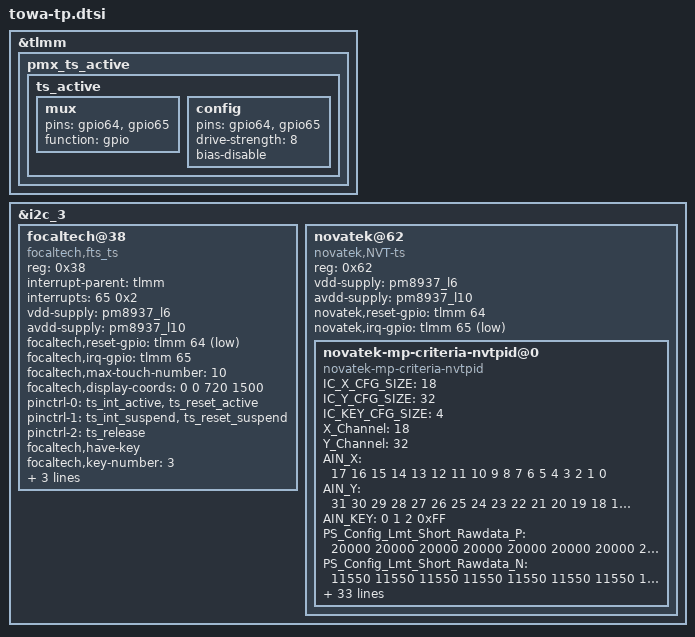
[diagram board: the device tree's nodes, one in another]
/*
 * Copyright (c) 2015, The Linux Foundation. All rights reserved.
 *
 * This program is free software; you can redistribute it and/or modify
 * it under the terms of the GNU General Public License version 2 and
 * only version 2 as published by the Free Software Foundation.
 *
 * This program is distributed in the hope that it will be useful,
 * but WITHOUT ANY WARRANTY; without even the implied warranty of
 * MERCHANTABILITY or FITNESS FOR A PARTICULAR PURPOSE.  See the
 * GNU General Public License for more details.
 */

&tlmm {
	pmx_ts_active {
		ts_active: ts_active {
			mux {
				pins = "gpio64","gpio65";
				function = "gpio";
			};

			config {
				pins = "gpio64","gpio65";
				drive-strength = <8>;
				bias-disable; /* NO pull */
			};
		};
	};
};

&i2c_3 {
	status = "ok";
	/* focaltech device tree node */
        focaltech@38 {
                compatible = "focaltech,fts_ts";
                reg = <0x38>;
                interrupt-parent = <&tlmm>;
                interrupts = <65 0x2>;
		vdd-supply = <&pm8937_l6>;    //VDDIO
		avdd-supply = <&pm8937_l10>;    //VDD

                focaltech,reset-gpio = <&tlmm 64 0x01>;
                focaltech,irq-gpio = <&tlmm 65 0x02>;

		/* INT脚 */
		focaltech,max-touch-number = <10>;
		/* 最大触点数 */
		focaltech,display-coords = <0 0 720 1500>;
		/* 分辨率 */

                /* pins used by touchscreen */
                pinctrl-names = "pmx_ts_active",
                                "pmx_ts_suspend",
                                "pmx_ts_release";
                pinctrl-0 = <&ts_int_active &ts_reset_active>;
                pinctrl-1 = <&ts_int_suspend &ts_reset_suspend>;
                pinctrl-2 = <&ts_release>;
		/* 按键配置 */
		/*focaltech,have-key;*/
		/* 无按键 */
		/* 有按键 */
		focaltech,have-key;
		focaltech,key-number = <3>; /* 按键个数 */
		focaltech,keys = <139 172 158>; /* 按键值,参考上面*/
		focaltech,key-y-coord = <2000>; /* 按键Y坐标 */
		focaltech,key-x-coords = <200 600 800>; /* 按键对应的X坐标 */
	};

	/* Novatek device tree node */
	novatek@62 {
		compatible = "novatek,NVT-ts";
		reg = <0x62>;
		status = "ok";

		vdd-supply = <&pm8937_l6>;    //VDDIO
		avdd-supply = <&pm8937_l10>;    //VDD

		novatek,reset-gpio = <&tlmm 64 0x00>;
		novatek,irq-gpio = <&tlmm 65 0x2001>;

		/* MP */
		//novatek,mp-support-dt;

		novatek-mp-criteria-nvtpid@0 {
			#address-cells = <1>;
			#size-cells = <0>;
			compatible = "novatek-mp-criteria-nvtpid";

			/* MP Config */
			IC_X_CFG_SIZE = <18>;
			IC_Y_CFG_SIZE = <32>;
			IC_KEY_CFG_SIZE = <4>;
			X_Channel = <18>;
			Y_Channel = <32>;
			AIN_X = <17 16 15 14 13 12 11 10 9 8 7 6 5 4 3 2 1 0>;
			AIN_Y = <31 30 29 28 27 26 25 24 23 22 21 20 19 18 17 16 15
								14 13 12 11 10 9 8 7 6 5 4 3 2 1 0>;
			AIN_KEY = <0 1 2 0xFF>;

			/* MP Criteria */
			PS_Config_Lmt_Short_Rawdata_P = <
				20000 20000 20000 20000 20000 20000 20000 20000 20000 20000 20000 20000 20000 20000 20000 20000 20000 20000
				20000 20000 20000 20000 20000 20000 20000 20000 20000 20000 20000 20000 20000 20000 20000 20000 20000 20000
				20000 20000 20000 20000 20000 20000 20000 20000 20000 20000 20000 20000 20000 20000 20000 20000 20000 20000
				20000 20000 20000 20000 20000 20000 20000 20000 20000 20000 20000 20000 20000 20000 20000 20000 20000 20000
				20000 20000 20000 20000 20000 20000 20000 20000 20000 20000 20000 20000 20000 20000 20000 20000 20000 20000
				20000 20000 20000 20000 20000 20000 20000 20000 20000 20000 20000 20000 20000 20000 20000 20000 20000 20000
				20000 20000 20000 20000 20000 20000 20000 20000 20000 20000 20000 20000 20000 20000 20000 20000 20000 20000
				20000 20000 20000 20000 20000 20000 20000 20000 20000 20000 20000 20000 20000 20000 20000 20000 20000 20000
				20000 20000 20000 20000 20000 20000 20000 20000 20000 20000 20000 20000 20000 20000 20000 20000 20000 20000
				20000 20000 20000 20000 20000 20000 20000 20000 20000 20000 20000 20000 20000 20000 20000 20000 20000 20000
				20000 20000 20000 20000 20000 20000 20000 20000 20000 20000 20000 20000 20000 20000 20000 20000 20000 20000
				20000 20000 20000 20000 20000 20000 20000 20000 20000 20000 20000 20000 20000 20000 20000 20000 20000 20000
				20000 20000 20000 20000 20000 20000 20000 20000 20000 20000 20000 20000 20000 20000 20000 20000 20000 20000
				20000 20000 20000 20000 20000 20000 20000 20000 20000 20000 20000 20000 20000 20000 20000 20000 20000 20000
				20000 20000 20000 20000 20000 20000 20000 20000 20000 20000 20000 20000 20000 20000 20000 20000 20000 20000
				20000 20000 20000 20000 20000 20000 20000 20000 20000 20000 20000 20000 20000 20000 20000 20000 20000 20000
				20000 20000 20000 20000 20000 20000 20000 20000 20000 20000 20000 20000 20000 20000 20000 20000 20000 20000
				20000 20000 20000 20000 20000 20000 20000 20000 20000 20000 20000 20000 20000 20000 20000 20000 20000 20000
				20000 20000 20000 20000 20000 20000 20000 20000 20000 20000 20000 20000 20000 20000 20000 20000 20000 20000
				20000 20000 20000 20000 20000 20000 20000 20000 20000 20000 20000 20000 20000 20000 20000 20000 20000 20000
				20000 20000 20000 20000 20000 20000 20000 20000 20000 20000 20000 20000 20000 20000 20000 20000 20000 20000
				20000 20000 20000 20000 20000 20000 20000 20000 20000 20000 20000 20000 20000 20000 20000 20000 20000 20000
				20000 20000 20000 20000 20000 20000 20000 20000 20000 20000 20000 20000 20000 20000 20000 20000 20000 20000
				20000 20000 20000 20000 20000 20000 20000 20000 20000 20000 20000 20000 20000 20000 20000 20000 20000 20000
				20000 20000 20000 20000 20000 20000 20000 20000 20000 20000 20000 20000 20000 20000 20000 20000 20000 20000
				20000 20000 20000 20000 20000 20000 20000 20000 20000 20000 20000 20000 20000 20000 20000 20000 20000 20000
				20000 20000 20000 20000 20000 20000 20000 20000 20000 20000 20000 20000 20000 20000 20000 20000 20000 20000
				20000 20000 20000 20000 20000 20000 20000 20000 20000 20000 20000 20000 20000 20000 20000 20000 20000 20000
				20000 20000 20000 20000 20000 20000 20000 20000 20000 20000 20000 20000 20000 20000 20000 20000 20000 20000
				20000 20000 20000 20000 20000 20000 20000 20000 20000 20000 20000 20000 20000 20000 20000 20000 20000 20000
				20000 20000 20000 20000 20000 20000 20000 20000 20000 20000 20000 20000 20000 20000 20000 20000 20000 20000
				20000 20000 20000 20000 20000 20000 20000 20000 20000 20000 20000 20000 20000 20000 20000 20000 20000 20000
				20000 20000 20000>;

			PS_Config_Lmt_Short_Rawdata_N = <
				11550 11550 11550 11550 11550 11550 11550 11550 11550 11550 11550 11550 11550 11550 11550 11550 11550 11550
				11550 11550 11550 11550 11550 11550 11550 11550 11550 11550 11550 11550 11550 11550 11550 11550 11550 11550
				11550 11550 11550 11550 11550 11550 11550 11550 11550 11550 11550 11550 11550 11550 11550 11550 11550 11550
				11550 11550 11550 11550 11550 11550 11550 11550 11550 11550 11550 11550 11550 11550 11550 11550 11550 11550
				11550 11550 11550 11550 11550 11550 11550 11550 11550 11550 11550 11550 11550 11550 11550 11550 11550 11550
				11550 11550 11550 11550 11550 11550 11550 11550 11550 11550 11550 11550 11550 11550 11550 11550 11550 11550
				11550 11550 11550 11550 11550 11550 11550 11550 11550 11550 11550 11550 11550 11550 11550 11550 11550 11550
				11550 11550 11550 11550 11550 11550 11550 11550 11550 11550 11550 11550 11550 11550 11550 11550 11550 11550
				11550 11550 11550 11550 11550 11550 11550 11550 11550 11550 11550 11550 11550 11550 11550 11550 11550 11550
				11550 11550 11550 11550 11550 11550 11550 11550 11550 11550 11550 11550 11550 11550 11550 11550 11550 11550
				11550 11550 11550 11550 11550 11550 11550 11550 11550 11550 11550 11550 11550 11550 11550 11550 11550 11550
				11550 11550 11550 11550 11550 11550 11550 11550 11550 11550 11550 11550 11550 11550 11550 11550 11550 11550
				11550 11550 11550 11550 11550 11550 11550 11550 11550 11550 11550 11550 11550 11550 11550 11550 11550 11550
				11550 11550 11550 11550 11550 11550 11550 11550 11550 11550 11550 11550 11550 11550 11550 11550 11550 11550
				11550 11550 11550 11550 11550 11550 11550 11550 11550 11550 11550 11550 11550 11550 11550 11550 11550 11550
				11550 11550 11550 11550 11550 11550 11550 11550 11550 11550 11550 11550 11550 11550 11550 11550 11550 11550
				11550 11550 11550 11550 11550 11550 11550 11550 11550 11550 11550 11550 11550 11550 11550 11550 11550 11550
				11550 11550 11550 11550 11550 11550 11550 11550 11550 11550 11550 11550 11550 11550 11550 11550 11550 11550
				11550 11550 11550 11550 11550 11550 11550 11550 11550 11550 11550 11550 11550 11550 11550 11550 11550 11550
				11550 11550 11550 11550 11550 11550 11550 11550 11550 11550 11550 11550 11550 11550 11550 11550 11550 11550
				11550 11550 11550 11550 11550 11550 11550 11550 11550 11550 11550 11550 11550 11550 11550 11550 11550 11550
				11550 11550 11550 11550 11550 11550 11550 11550 11550 11550 11550 11550 11550 11550 11550 11550 11550 11550
				11550 11550 11550 11550 11550 11550 11550 11550 11550 11550 11550 11550 11550 11550 11550 11550 11550 11550
				11550 11550 11550 11550 11550 11550 11550 11550 11550 11550 11550 11550 11550 11550 11550 11550 11550 11550
				11550 11550 11550 11550 11550 11550 11550 11550 11550 11550 11550 11550 11550 11550 11550 11550 11550 11550
				11550 11550 11550 11550 11550 11550 11550 11550 11550 11550 11550 11550 11550 11550 11550 11550 11550 11550
				11550 11550 11550 11550 11550 11550 11550 11550 11550 11550 11550 11550 11550 11550 11550 11550 11550 11550
				11550 11550 11550 11550 11550 11550 11550 11550 11550 11550 11550 11550 11550 11550 11550 11550 11550 11550
				11550 11550 11550 11550 11550 11550 11550 11550 11550 11550 11550 11550 11550 11550 11550 11550 11550 11550
				11550 11550 11550 11550 11550 11550 11550 11550 11550 11550 11550 11550 11550 11550 11550 11550 11550 11550
				11550 11550 11550 11550 11550 11550 11550 11550 11550 11550 11550 11550 11550 11550 11550 11550 11550 11550
				11550 11550 11550 11550 11550 11550 11550 11550 11550 11550 11550 11550 11550 11550 11550 11550 11550 11550
				11550 11550 11550>;

			PS_Config_Lmt_Short_Diff_P = <
				6300 6300 6300 6300 6300 6300 6300 6300 6300 6300 6300 6300 6300 6300 6300 6300 6300 6300
				6300 6300 6300 6300 6300 6300 6300 6300 6300 6300 6300 6300 6300 6300 6300 6300 6300 6300
				6300 6300 6300 6300 6300 6300 6300 6300 6300 6300 6300 6300 6300 6300 6300 6300 6300 6300
				6300 6300 6300 6300 6300 6300 6300 6300 6300 6300 6300 6300 6300 6300 6300 6300 6300 6300
				6300 6300 6300 6300 6300 6300 6300 6300 6300 6300 6300 6300 6300 6300 6300 6300 6300 6300
				6300 6300 6300 6300 6300 6300 6300 6300 6300 6300 6300 6300 6300 6300 6300 6300 6300 6300
				6300 6300 6300 6300 6300 6300 6300 6300 6300 6300 6300 6300 6300 6300 6300 6300 6300 6300
				6300 6300 6300 6300 6300 6300 6300 6300 6300 6300 6300 6300 6300 6300 6300 6300 6300 6300
				6300 6300 6300 6300 6300 6300 6300 6300 6300 6300 6300 6300 6300 6300 6300 6300 6300 6300
				6300 6300 6300 6300 6300 6300 6300 6300 6300 6300 6300 6300 6300 6300 6300 6300 6300 6300
				6300 6300 6300 6300 6300 6300 6300 6300 6300 6300 6300 6300 6300 6300 6300 6300 6300 6300
				6300 6300 6300 6300 6300 6300 6300 6300 6300 6300 6300 6300 6300 6300 6300 6300 6300 6300
				6300 6300 6300 6300 6300 6300 6300 6300 6300 6300 6300 6300 6300 6300 6300 6300 6300 6300
				6300 6300 6300 6300 6300 6300 6300 6300 6300 6300 6300 6300 6300 6300 6300 6300 6300 6300
				6300 6300 6300 6300 6300 6300 6300 6300 6300 6300 6300 6300 6300 6300 6300 6300 6300 6300
				6300 6300 6300 6300 6300 6300 6300 6300 6300 6300 6300 6300 6300 6300 6300 6300 6300 6300
				6300 6300 6300 6300 6300 6300 6300 6300 6300 6300 6300 6300 6300 6300 6300 6300 6300 6300
				6300 6300 6300 6300 6300 6300 6300 6300 6300 6300 6300 6300 6300 6300 6300 6300 6300 6300
				6300 6300 6300 6300 6300 6300 6300 6300 6300 6300 6300 6300 6300 6300 6300 6300 6300 6300
				6300 6300 6300 6300 6300 6300 6300 6300 6300 6300 6300 6300 6300 6300 6300 6300 6300 6300
				6300 6300 6300 6300 6300 6300 6300 6300 6300 6300 6300 6300 6300 6300 6300 6300 6300 6300
				6300 6300 6300 6300 6300 6300 6300 6300 6300 6300 6300 6300 6300 6300 6300 6300 6300 6300
				6300 6300 6300 6300 6300 6300 6300 6300 6300 6300 6300 6300 6300 6300 6300 6300 6300 6300
				6300 6300 6300 6300 6300 6300 6300 6300 6300 6300 6300 6300 6300 6300 6300 6300 6300 6300
				6300 6300 6300 6300 6300 6300 6300 6300 6300 6300 6300 6300 6300 6300 6300 6300 6300 6300
				6300 6300 6300 6300 6300 6300 6300 6300 6300 6300 6300 6300 6300 6300 6300 6300 6300 6300
				6300 6300 6300 6300 6300 6300 6300 6300 6300 6300 6300 6300 6300 6300 6300 6300 6300 6300
				6300 6300 6300 6300 6300 6300 6300 6300 6300 6300 6300 6300 6300 6300 6300 6300 6300 6300
				6300 6300 6300 6300 6300 6300 6300 6300 6300 6300 6300 6300 6300 6300 6300 6300 6300 6300
				6300 6300 6300 6300 6300 6300 6300 6300 6300 6300 6300 6300 6300 6300 6300 6300 6300 6300
				6300 6300 6300 6300 6300 6300 6300 6300 6300 6300 6300 6300 6300 6300 6300 6300 6300 6300
				6300 6300 6300 6300 6300 6300 6300 6300 6300 6300 6300 6300 6300 6300 6300 6300 6300 6300
				6300 6300 6300>;

			PS_Config_Lmt_Short_Diff_N = <
				0 0 0 0 0 0 0 0 0 0 0 0 0 0 0 0 0 0
				0 0 0 0 0 0 0 0 0 0 0 0 0 0 0 0 0 0
				0 0 0 0 0 0 0 0 0 0 0 0 0 0 0 0 0 0
				0 0 0 0 0 0 0 0 0 0 0 0 0 0 0 0 0 0
				0 0 0 0 0 0 0 0 0 0 0 0 0 0 0 0 0 0
				0 0 0 0 0 0 0 0 0 0 0 0 0 0 0 0 0 0
				0 0 0 0 0 0 0 0 0 0 0 0 0 0 0 0 0 0
				0 0 0 0 0 0 0 0 0 0 0 0 0 0 0 0 0 0
				0 0 0 0 0 0 0 0 0 0 0 0 0 0 0 0 0 0
				0 0 0 0 0 0 0 0 0 0 0 0 0 0 0 0 0 0
				0 0 0 0 0 0 0 0 0 0 0 0 0 0 0 0 0 0
				0 0 0 0 0 0 0 0 0 0 0 0 0 0 0 0 0 0
				0 0 0 0 0 0 0 0 0 0 0 0 0 0 0 0 0 0
				0 0 0 0 0 0 0 0 0 0 0 0 0 0 0 0 0 0
				0 0 0 0 0 0 0 0 0 0 0 0 0 0 0 0 0 0
				0 0 0 0 0 0 0 0 0 0 0 0 0 0 0 0 0 0
				0 0 0 0 0 0 0 0 0 0 0 0 0 0 0 0 0 0
				0 0 0 0 0 0 0 0 0 0 0 0 0 0 0 0 0 0
				0 0 0 0 0 0 0 0 0 0 0 0 0 0 0 0 0 0
				0 0 0 0 0 0 0 0 0 0 0 0 0 0 0 0 0 0
				0 0 0 0 0 0 0 0 0 0 0 0 0 0 0 0 0 0
				0 0 0 0 0 0 0 0 0 0 0 0 0 0 0 0 0 0
				0 0 0 0 0 0 0 0 0 0 0 0 0 0 0 0 0 0
				0 0 0 0 0 0 0 0 0 0 0 0 0 0 0 0 0 0
				0 0 0 0 0 0 0 0 0 0 0 0 0 0 0 0 0 0
				0 0 0 0 0 0 0 0 0 0 0 0 0 0 0 0 0 0
				0 0 0 0 0 0 0 0 0 0 0 0 0 0 0 0 0 0
				0 0 0 0 0 0 0 0 0 0 0 0 0 0 0 0 0 0
				0 0 0 0 0 0 0 0 0 0 0 0 0 0 0 0 0 0
				0 0 0 0 0 0 0 0 0 0 0 0 0 0 0 0 0 0
				0 0 0 0 0 0 0 0 0 0 0 0 0 0 0 0 0 0
				0 0 0 0 0 0 0 0 0 0 0 0 0 0 0 0 0 0
				0 0 0>;

			PS_Config_Lmt_Short_Base_P = <
				2000 2000 2000 2000 2000 2000 2000 2000 2000 2000 2000 2000 2000 2000 2000 2000 2000 2000
				2000 2000 2000 2000 2000 2000 2000 2000 2000 2000 2000 2000 2000 2000 2000 2000 2000 2000
				2000 2000 2000 2000 2000 2000 2000 2000 2000 2000 2000 2000 2000 2000 2000 2000 2000 2000
				2000 2000 2000 2000 2000 2000 2000 2000 2000 2000 2000 2000 2000 2000 2000 2000 2000 2000
				2000 2000 2000 2000 2000 2000 2000 2000 2000 2000 2000 2000 2000 2000 2000 2000 2000 2000
				2000 2000 2000 2000 2000 2000 2000 2000 2000 2000 2000 2000 2000 2000 2000 2000 2000 2000
				2000 2000 2000 2000 2000 2000 2000 2000 2000 2000 2000 2000 2000 2000 2000 2000 2000 2000
				2000 2000 2000 2000 2000 2000 2000 2000 2000 2000 2000 2000 2000 2000 2000 2000 2000 2000
				2000 2000 2000 2000 2000 2000 2000 2000 2000 2000 2000 2000 2000 2000 2000 2000 2000 2000
				2000 2000 2000 2000 2000 2000 2000 2000 2000 2000 2000 2000 2000 2000 2000 2000 2000 2000
				2000 2000 2000 2000 2000 2000 2000 2000 2000 2000 2000 2000 2000 2000 2000 2000 2000 2000
				2000 2000 2000 2000 2000 2000 2000 2000 2000 2000 2000 2000 2000 2000 2000 2000 2000 2000
				2000 2000 2000 2000 2000 2000 2000 2000 2000 2000 2000 2000 2000 2000 2000 2000 2000 2000
				2000 2000 2000 2000 2000 2000 2000 2000 2000 2000 2000 2000 2000 2000 2000 2000 2000 2000
				2000 2000 2000 2000 2000 2000 2000 2000 2000 2000 2000 2000 2000 2000 2000 2000 2000 2000
				2000 2000 2000 2000 2000 2000 2000 2000 2000 2000 2000 2000 2000 2000 2000 2000 2000 2000
				2000 2000 2000 2000 2000 2000 2000 2000 2000 2000 2000 2000 2000 2000 2000 2000 2000 2000
				2000 2000 2000 2000 2000 2000 2000 2000 2000 2000 2000 2000 2000 2000 2000 2000 2000 2000
				2000 2000 2000 2000 2000 2000 2000 2000 2000 2000 2000 2000 2000 2000 2000 2000 2000 2000
				2000 2000 2000 2000 2000 2000 2000 2000 2000 2000 2000 2000 2000 2000 2000 2000 2000 2000
				2000 2000 2000 2000 2000 2000 2000 2000 2000 2000 2000 2000 2000 2000 2000 2000 2000 2000
				2000 2000 2000 2000 2000 2000 2000 2000 2000 2000 2000 2000 2000 2000 2000 2000 2000 2000
				2000 2000 2000 2000 2000 2000 2000 2000 2000 2000 2000 2000 2000 2000 2000 2000 2000 2000
				2000 2000 2000 2000 2000 2000 2000 2000 2000 2000 2000 2000 2000 2000 2000 2000 2000 2000
				2000 2000 2000 2000 2000 2000 2000 2000 2000 2000 2000 2000 2000 2000 2000 2000 2000 2000
				2000 2000 2000 2000 2000 2000 2000 2000 2000 2000 2000 2000 2000 2000 2000 2000 2000 2000
				2000 2000 2000 2000 2000 2000 2000 2000 2000 2000 2000 2000 2000 2000 2000 2000 2000 2000
				2000 2000 2000 2000 2000 2000 2000 2000 2000 2000 2000 2000 2000 2000 2000 2000 2000 2000
				2000 2000 2000 2000 2000 2000 2000 2000 2000 2000 2000 2000 2000 2000 2000 2000 2000 2000
				2000 2000 2000 2000 2000 2000 2000 2000 2000 2000 2000 2000 2000 2000 2000 2000 2000 2000
				2000 2000 2000 2000 2000 2000 2000 2000 2000 2000 2000 2000 2000 2000 2000 2000 2000 2000
				2000 2000 2000 2000 2000 2000 2000 2000 2000 2000 2000 2000 2000 2000 2000 2000 2000 2000
				2000 2000 2000>;

			PS_Config_Lmt_Short_Base_N = <
				(-2000) (-2000) (-2000) (-2000) (-2000) (-2000) (-2000) (-2000) (-2000) (-2000) (-2000) (-2000) (-2000) (-2000) (-2000) (-2000) (-2000) (-2000)
				(-2000) (-2000) (-2000) (-2000) (-2000) (-2000) (-2000) (-2000) (-2000) (-2000) (-2000) (-2000) (-2000) (-2000) (-2000) (-2000) (-2000) (-2000)
				(-2000) (-2000) (-2000) (-2000) (-2000) (-2000) (-2000) (-2000) (-2000) (-2000) (-2000) (-2000) (-2000) (-2000) (-2000) (-2000) (-2000) (-2000)
				(-2000) (-2000) (-2000) (-2000) (-2000) (-2000) (-2000) (-2000) (-2000) (-2000) (-2000) (-2000) (-2000) (-2000) (-2000) (-2000) (-2000) (-2000)
				(-2000) (-2000) (-2000) (-2000) (-2000) (-2000) (-2000) (-2000) (-2000) (-2000) (-2000) (-2000) (-2000) (-2000) (-2000) (-2000) (-2000) (-2000)
				(-2000) (-2000) (-2000) (-2000) (-2000) (-2000) (-2000) (-2000) (-2000) (-2000) (-2000) (-2000) (-2000) (-2000) (-2000) (-2000) (-2000) (-2000)
				(-2000) (-2000) (-2000) (-2000) (-2000) (-2000) (-2000) (-2000) (-2000) (-2000) (-2000) (-2000) (-2000) (-2000) (-2000) (-2000) (-2000) (-2000)
				(-2000) (-2000) (-2000) (-2000) (-2000) (-2000) (-2000) (-2000) (-2000) (-2000) (-2000) (-2000) (-2000) (-2000) (-2000) (-2000) (-2000) (-2000)
				(-2000) (-2000) (-2000) (-2000) (-2000) (-2000) (-2000) (-2000) (-2000) (-2000) (-2000) (-2000) (-2000) (-2000) (-2000) (-2000) (-2000) (-2000)
				(-2000) (-2000) (-2000) (-2000) (-2000) (-2000) (-2000) (-2000) (-2000) (-2000) (-2000) (-2000) (-2000) (-2000) (-2000) (-2000) (-2000) (-2000)
				(-2000) (-2000) (-2000) (-2000) (-2000) (-2000) (-2000) (-2000) (-2000) (-2000) (-2000) (-2000) (-2000) (-2000) (-2000) (-2000) (-2000) (-2000)
				(-2000) (-2000) (-2000) (-2000) (-2000) (-2000) (-2000) (-2000) (-2000) (-2000) (-2000) (-2000) (-2000) (-2000) (-2000) (-2000) (-2000) (-2000)
				(-2000) (-2000) (-2000) (-2000) (-2000) (-2000) (-2000) (-2000) (-2000) (-2000) (-2000) (-2000) (-2000) (-2000) (-2000) (-2000) (-2000) (-2000)
				(-2000) (-2000) (-2000) (-2000) (-2000) (-2000) (-2000) (-2000) (-2000) (-2000) (-2000) (-2000) (-2000) (-2000) (-2000) (-2000) (-2000) (-2000)
				(-2000) (-2000) (-2000) (-2000) (-2000) (-2000) (-2000) (-2000) (-2000) (-2000) (-2000) (-2000) (-2000) (-2000) (-2000) (-2000) (-2000) (-2000)
				(-2000) (-2000) (-2000) (-2000) (-2000) (-2000) (-2000) (-2000) (-2000) (-2000) (-2000) (-2000) (-2000) (-2000) (-2000) (-2000) (-2000) (-2000)
				(-2000) (-2000) (-2000) (-2000) (-2000) (-2000) (-2000) (-2000) (-2000) (-2000) (-2000) (-2000) (-2000) (-2000) (-2000) (-2000) (-2000) (-2000)
				(-2000) (-2000) (-2000) (-2000) (-2000) (-2000) (-2000) (-2000) (-2000) (-2000) (-2000) (-2000) (-2000) (-2000) (-2000) (-2000) (-2000) (-2000)
				(-2000) (-2000) (-2000) (-2000) (-2000) (-2000) (-2000) (-2000) (-2000) (-2000) (-2000) (-2000) (-2000) (-2000) (-2000) (-2000) (-2000) (-2000)
				(-2000) (-2000) (-2000) (-2000) (-2000) (-2000) (-2000) (-2000) (-2000) (-2000) (-2000) (-2000) (-2000) (-2000) (-2000) (-2000) (-2000) (-2000)
				(-2000) (-2000) (-2000) (-2000) (-2000) (-2000) (-2000) (-2000) (-2000) (-2000) (-2000) (-2000) (-2000) (-2000) (-2000) (-2000) (-2000) (-2000)
				(-2000) (-2000) (-2000) (-2000) (-2000) (-2000) (-2000) (-2000) (-2000) (-2000) (-2000) (-2000) (-2000) (-2000) (-2000) (-2000) (-2000) (-2000)
				(-2000) (-2000) (-2000) (-2000) (-2000) (-2000) (-2000) (-2000) (-2000) (-2000) (-2000) (-2000) (-2000) (-2000) (-2000) (-2000) (-2000) (-2000)
				(-2000) (-2000) (-2000) (-2000) (-2000) (-2000) (-2000) (-2000) (-2000) (-2000) (-2000) (-2000) (-2000) (-2000) (-2000) (-2000) (-2000) (-2000)
				(-2000) (-2000) (-2000) (-2000) (-2000) (-2000) (-2000) (-2000) (-2000) (-2000) (-2000) (-2000) (-2000) (-2000) (-2000) (-2000) (-2000) (-2000)
				(-2000) (-2000) (-2000) (-2000) (-2000) (-2000) (-2000) (-2000) (-2000) (-2000) (-2000) (-2000) (-2000) (-2000) (-2000) (-2000) (-2000) (-2000)
				(-2000) (-2000) (-2000) (-2000) (-2000) (-2000) (-2000) (-2000) (-2000) (-2000) (-2000) (-2000) (-2000) (-2000) (-2000) (-2000) (-2000) (-2000)
				(-2000) (-2000) (-2000) (-2000) (-2000) (-2000) (-2000) (-2000) (-2000) (-2000) (-2000) (-2000) (-2000) (-2000) (-2000) (-2000) (-2000) (-2000)
				(-2000) (-2000) (-2000) (-2000) (-2000) (-2000) (-2000) (-2000) (-2000) (-2000) (-2000) (-2000) (-2000) (-2000) (-2000) (-2000) (-2000) (-2000)
				(-2000) (-2000) (-2000) (-2000) (-2000) (-2000) (-2000) (-2000) (-2000) (-2000) (-2000) (-2000) (-2000) (-2000) (-2000) (-2000) (-2000) (-2000)
				(-2000) (-2000) (-2000) (-2000) (-2000) (-2000) (-2000) (-2000) (-2000) (-2000) (-2000) (-2000) (-2000) (-2000) (-2000) (-2000) (-2000) (-2000)
				(-2000) (-2000) (-2000) (-2000) (-2000) (-2000) (-2000) (-2000) (-2000) (-2000) (-2000) (-2000) (-2000) (-2000) (-2000) (-2000) (-2000) (-2000)
				(-2000) (-2000) (-2000)>;

			PS_Config_Lmt_Open_Rawdata_P = <
				13000 13000 13000 13000 13000 13000 13000 13000 13000 13000 13000 13000 13000 13000 13000 13000 13000 13000
				13000 13000 13000 13000 13000 13000 13000 13000 13000 13000 13000 13000 13000 13000 13000 13000 13000 13000
				13000 13000 13000 13000 13000 13000 13000 13000 13000 13000 13000 13000 13000 13000 13000 13000 13000 13000
				13000 13000 13000 13000 13000 13000 13000 13000 13000 13000 13000 13000 13000 13000 13000 13000 13000 13000
				13000 13000 13000 13000 13000 13000 13000 13000 13000 13000 13000 13000 13000 13000 13000 13000 13000 13000
				13000 13000 13000 13000 13000 13000 13000 13000 13000 13000 13000 13000 13000 13000 13000 13000 13000 13000
				13000 13000 13000 13000 13000 13000 13000 13000 13000 13000 13000 13000 13000 13000 13000 13000 13000 13000
				13000 13000 13000 13000 13000 13000 13000 13000 13000 13000 13000 13000 13000 13000 13000 13000 13000 13000
				13000 13000 13000 13000 13000 13000 13000 13000 13000 13000 13000 13000 13000 13000 13000 13000 13000 13000
				13000 13000 13000 13000 13000 13000 13000 13000 13000 13000 13000 13000 13000 13000 13000 13000 13000 13000
				13000 13000 13000 13000 13000 13000 13000 13000 13000 13000 13000 13000 13000 13000 13000 13000 13000 13000
				13000 13000 13000 13000 13000 13000 13000 13000 13000 13000 13000 13000 13000 13000 13000 13000 13000 13000
				13000 13000 13000 13000 13000 13000 13000 13000 13000 13000 13000 13000 13000 13000 13000 13000 13000 13000
				13000 13000 13000 13000 13000 13000 13000 13000 13000 13000 13000 13000 13000 13000 13000 13000 13000 13000
				13000 13000 13000 13000 13000 13000 13000 13000 13000 13000 13000 13000 13000 13000 13000 13000 13000 13000
				13000 13000 13000 13000 13000 13000 13000 13000 13000 13000 13000 13000 13000 13000 13000 13000 13000 13000
				13000 13000 13000 13000 13000 13000 13000 13000 13000 13000 13000 13000 13000 13000 13000 13000 13000 13000
				13000 13000 13000 13000 13000 13000 13000 13000 13000 13000 13000 13000 13000 13000 13000 13000 13000 13000
				13000 13000 13000 13000 13000 13000 13000 13000 13000 13000 13000 13000 13000 13000 13000 13000 13000 13000
				13000 13000 13000 13000 13000 13000 13000 13000 13000 13000 13000 13000 13000 13000 13000 13000 13000 13000
				13000 13000 13000 13000 13000 13000 13000 13000 13000 13000 13000 13000 13000 13000 13000 13000 13000 13000
				13000 13000 13000 13000 13000 13000 13000 13000 13000 13000 13000 13000 13000 13000 13000 13000 13000 13000
				13000 13000 13000 13000 13000 13000 13000 13000 13000 13000 13000 13000 13000 13000 13000 13000 13000 13000
				13000 13000 13000 13000 13000 13000 13000 13000 13000 13000 13000 13000 13000 13000 13000 13000 13000 13000
				13000 13000 13000 13000 13000 13000 13000 13000 13000 13000 13000 13000 13000 13000 13000 13000 13000 13000
				13000 13000 13000 13000 13000 13000 13000 13000 13000 13000 13000 13000 13000 13000 13000 13000 13000 13000
				13000 13000 13000 13000 13000 13000 13000 13000 13000 13000 13000 13000 13000 13000 13000 13000 13000 13000
				13000 13000 13000 13000 13000 13000 13000 13000 13000 13000 13000 13000 13000 13000 13000 13000 13000 13000
				13000 13000 13000 13000 13000 13000 13000 13000 13000 13000 13000 13000 13000 13000 13000 13000 13000 13000
				13000 13000 13000 13000 13000 13000 13000 13000 13000 13000 13000 13000 13000 13000 13000 13000 13000 13000
				13000 13000 13000 13000 13000 13000 13000 13000 13000 13000 13000 13000 13000 13000 13000 13000 13000 13000
				13000 13000 13000 13000 13000 13000 13000 13000 13000 13000 13000 13000 13000 13000 13000 13000 13000 13000
				13000 13000 13000>;

			PS_Config_Lmt_Open_Rawdata_N = <
				6500 6500 6500 6500 6500 6500 6500 6500 6500 6500 6500 6500 6500 6500 6500 6500 6500 6500
				6500 6500 6500 6500 6500 6500 6500 6500 6500 6500 6500 6500 6500 6500 6500 6500 6500 6500
				6500 6500 6500 6500 6500 6500 6500 6500 6500 6500 6500 6500 6500 6500 6500 6500 6500 6500
				6500 6500 6500 6500 6500 6500 6500 6500 6500 6500 6500 6500 6500 6500 6500 6500 6500 6500
				6500 6500 6500 6500 6500 6500 6500 6500 6500 6500 6500 6500 6500 6500 6500 6500 6500 6500
				6500 6500 6500 6500 6500 6500 6500 6500 6500 6500 6500 6500 6500 6500 6500 6500 6500 6500
				6500 6500 6500 6500 6500 6500 6500 6500 6500 6500 6500 6500 6500 6500 6500 6500 6500 6500
				6500 6500 6500 6500 6500 6500 6500 6500 6500 6500 6500 6500 6500 6500 6500 6500 6500 6500
				6500 6500 6500 6500 6500 6500 6500 6500 6500 6500 6500 6500 6500 6500 6500 6500 6500 6500
				6500 6500 6500 6500 6500 6500 6500 6500 6500 6500 6500 6500 6500 6500 6500 6500 6500 6500
				6500 6500 6500 6500 6500 6500 6500 6500 6500 6500 6500 6500 6500 6500 6500 6500 6500 6500
				6500 6500 6500 6500 6500 6500 6500 6500 6500 6500 6500 6500 6500 6500 6500 6500 6500 6500
				6500 6500 6500 6500 6500 6500 6500 6500 6500 6500 6500 6500 6500 6500 6500 6500 6500 6500
				6500 6500 6500 6500 6500 6500 6500 6500 6500 6500 6500 6500 6500 6500 6500 6500 6500 6500
				6500 6500 6500 6500 6500 6500 6500 6500 6500 6500 6500 6500 6500 6500 6500 6500 6500 6500
				6500 6500 6500 6500 6500 6500 6500 6500 6500 6500 6500 6500 6500 6500 6500 6500 6500 6500
				6500 6500 6500 6500 6500 6500 6500 6500 6500 6500 6500 6500 6500 6500 6500 6500 6500 6500
				6500 6500 6500 6500 6500 6500 6500 6500 6500 6500 6500 6500 6500 6500 6500 6500 6500 6500
				6500 6500 6500 6500 6500 6500 6500 6500 6500 6500 6500 6500 6500 6500 6500 6500 6500 6500
				6500 6500 6500 6500 6500 6500 6500 6500 6500 6500 6500 6500 6500 6500 6500 6500 6500 6500
				6500 6500 6500 6500 6500 6500 6500 6500 6500 6500 6500 6500 6500 6500 6500 6500 6500 6500
				6500 6500 6500 6500 6500 6500 6500 6500 6500 6500 6500 6500 6500 6500 6500 6500 6500 6500
				6500 6500 6500 6500 6500 6500 6500 6500 6500 6500 6500 6500 6500 6500 6500 6500 6500 6500
				6500 6500 6500 6500 6500 6500 6500 6500 6500 6500 6500 6500 6500 6500 6500 6500 6500 6500
				6500 6500 6500 6500 6500 6500 6500 6500 6500 6500 6500 6500 6500 6500 6500 6500 6500 6500
				6500 6500 6500 6500 6500 6500 6500 6500 6500 6500 6500 6500 6500 6500 6500 6500 6500 6500
				6500 6500 6500 6500 6500 6500 6500 6500 6500 6500 6500 6500 6500 6500 6500 6500 6500 6500
				6500 6500 6500 6500 6500 6500 6500 6500 6500 6500 6500 6500 6500 6500 6500 6500 6500 6500
				6500 6500 6500 6500 6500 6500 6500 6500 6500 6500 6500 6500 6500 6500 6500 6500 6500 6500
				6500 6500 6500 6500 6500 6500 6500 6500 6500 6500 6500 6500 6500 6500 6500 6500 6500 6500
				6500 6500 6500 6500 6500 6500 6500 6500 6500 6500 6500 6500 6500 6500 6500 6500 6500 6500
				6500 6500 6500 6500 6500 6500 6500 6500 6500 6500 6500 6500 6500 6500 6500 6500 6500 6500
				6500 6500 6500>;

			PS_Config_Lmt_FW_Rawdata_P = <
				2000 2000 2000 2000 2000 2000 2000 2000 2000 2000 2000 2000 2000 2000 2000 2000 2000 2000
				2000 2000 2000 2000 2000 2000 2000 2000 2000 2000 2000 2000 2000 2000 2000 2000 2000 2000
				2000 2000 2000 2000 2000 2000 2000 2000 2000 2000 2000 2000 2000 2000 2000 2000 2000 2000
				2000 2000 2000 2000 2000 2000 2000 2000 2000 2000 2000 2000 2000 2000 2000 2000 2000 2000
				2000 2000 2000 2000 2000 2000 2000 2000 2000 2000 2000 2000 2000 2000 2000 2000 2000 2000
				2000 2000 2000 2000 2000 2000 2000 2000 2000 2000 2000 2000 2000 2000 2000 2000 2000 2000
				2000 2000 2000 2000 2000 2000 2000 2000 2000 2000 2000 2000 2000 2000 2000 2000 2000 2000
				2000 2000 2000 2000 2000 2000 2000 2000 2000 2000 2000 2000 2000 2000 2000 2000 2000 2000
				2000 2000 2000 2000 2000 2000 2000 2000 2000 2000 2000 2000 2000 2000 2000 2000 2000 2000
				2000 2000 2000 2000 2000 2000 2000 2000 2000 2000 2000 2000 2000 2000 2000 2000 2000 2000
				2000 2000 2000 2000 2000 2000 2000 2000 2000 2000 2000 2000 2000 2000 2000 2000 2000 2000
				2000 2000 2000 2000 2000 2000 2000 2000 2000 2000 2000 2000 2000 2000 2000 2000 2000 2000
				2000 2000 2000 2000 2000 2000 2000 2000 2000 2000 2000 2000 2000 2000 2000 2000 2000 2000
				2000 2000 2000 2000 2000 2000 2000 2000 2000 2000 2000 2000 2000 2000 2000 2000 2000 2000
				2000 2000 2000 2000 2000 2000 2000 2000 2000 2000 2000 2000 2000 2000 2000 2000 2000 2000
				2000 2000 2000 2000 2000 2000 2000 2000 2000 2000 2000 2000 2000 2000 2000 2000 2000 2000
				2000 2000 2000 2000 2000 2000 2000 2000 2000 2000 2000 2000 2000 2000 2000 2000 2000 2000
				2000 2000 2000 2000 2000 2000 2000 2000 2000 2000 2000 2000 2000 2000 2000 2000 2000 2000
				2000 2000 2000 2000 2000 2000 2000 2000 2000 2000 2000 2000 2000 2000 2000 2000 2000 2000
				2000 2000 2000 2000 2000 2000 2000 2000 2000 2000 2000 2000 2000 2000 2000 2000 2000 2000
				2000 2000 2000 2000 2000 2000 2000 2000 2000 2000 2000 2000 2000 2000 2000 2000 2000 2000
				2000 2000 2000 2000 2000 2000 2000 2000 2000 2000 2000 2000 2000 2000 2000 2000 2000 2000
				2000 2000 2000 2000 2000 2000 2000 2000 2000 2000 2000 2000 2000 2000 2000 2000 2000 2000
				2000 2000 2000 2000 2000 2000 2000 2000 2000 2000 2000 2000 2000 2000 2000 2000 2000 2000
				2000 2000 2000 2000 2000 2000 2000 2000 2000 2000 2000 2000 2000 2000 2000 2000 2000 2000
				2000 2000 2000 2000 2000 2000 2000 2000 2000 2000 2000 2000 2000 2000 2000 2000 2000 2000
				2000 2000 2000 2000 2000 2000 2000 2000 2000 2000 2000 2000 2000 2000 2000 2000 2000 2000
				2000 2000 2000 2000 2000 2000 2000 2000 2000 2000 2000 2000 2000 2000 2000 2000 2000 2000
				2000 2000 2000 2000 2000 2000 2000 2000 2000 2000 2000 2000 2000 2000 2000 2000 2000 2000
				2000 2000 2000 2000 2000 2000 2000 2000 2000 2000 2000 2000 2000 2000 2000 2000 2000 2000
				2000 2000 2000 2000 2000 2000 2000 2000 2000 2000 2000 2000 2000 2000 2000 2000 2000 2000
				2000 2000 2000 2000 2000 2000 2000 2000 2000 2000 2000 2000 2000 2000 2000 2000 2000 2000
				2000 2000 2000>;

			PS_Config_Lmt_FW_Rawdata_N = <
				400 400 400 400 400 400 400 400 400 400 400 400 400 400 400 400 400 400
				400 400 400 400 400 400 400 400 400 400 400 400 400 400 400 400 400 400
				400 400 400 400 400 400 400 400 400 400 400 400 400 400 400 400 400 400
				400 400 400 400 400 400 400 400 400 400 400 400 400 400 400 400 400 400
				400 400 400 400 400 400 400 400 400 400 400 400 400 400 400 400 400 400
				400 400 400 400 400 400 400 400 400 400 400 400 400 400 400 400 400 400
				400 400 400 400 400 400 400 400 400 400 400 400 400 400 400 400 400 400
				400 400 400 400 400 400 400 400 400 400 400 400 400 400 400 400 400 400
				400 400 400 400 400 400 400 400 400 400 400 400 400 400 400 400 400 400
				400 400 400 400 400 400 400 400 400 400 400 400 400 400 400 400 400 400
				400 400 400 400 400 400 400 400 400 400 400 400 400 400 400 400 400 400
				400 400 400 400 400 400 400 400 400 400 400 400 400 400 400 400 400 400
				400 400 400 400 400 400 400 400 400 400 400 400 400 400 400 400 400 400
				400 400 400 400 400 400 400 400 400 400 400 400 400 400 400 400 400 400
				400 400 400 400 400 400 400 400 400 400 400 400 400 400 400 400 400 400
				400 400 400 400 400 400 400 400 400 400 400 400 400 400 400 400 400 400
				400 400 400 400 400 400 400 400 400 400 400 400 400 400 400 400 400 400
				400 400 400 400 400 400 400 400 400 400 400 400 400 400 400 400 400 400
				400 400 400 400 400 400 400 400 400 400 400 400 400 400 400 400 400 400
				400 400 400 400 400 400 400 400 400 400 400 400 400 400 400 400 400 400
				400 400 400 400 400 400 400 400 400 400 400 400 400 400 400 400 400 400
				400 400 400 400 400 400 400 400 400 400 400 400 400 400 400 400 400 400
				400 400 400 400 400 400 400 400 400 400 400 400 400 400 400 400 400 400
				400 400 400 400 400 400 400 400 400 400 400 400 400 400 400 400 400 400
				400 400 400 400 400 400 400 400 400 400 400 400 400 400 400 400 400 400
				400 400 400 400 400 400 400 400 400 400 400 400 400 400 400 400 400 400
				400 400 400 400 400 400 400 400 400 400 400 400 400 400 400 400 400 400
				400 400 400 400 400 400 400 400 400 400 400 400 400 400 400 400 400 400
				400 400 400 400 400 400 400 400 400 400 400 400 400 400 400 400 400 400
				400 400 400 400 400 400 400 400 400 400 400 400 400 400 400 400 400 400
				400 400 400 400 400 400 400 400 400 400 400 400 400 400 400 400 400 400
				400 400 400 400 400 400 400 400 400 400 400 400 400 400 400 400 400 400
				400 400 400>;

			PS_Config_Lmt_FW_CC_P = <
				38 38 38 38 38 38 38 38 38 38 38 38 38 38 38 38 38 38
				38 38 38 38 38 38 38 38 38 38 38 38 38 38 38 38 38 38
				38 38 38 38 38 38 38 38 38 38 38 38 38 38 38 38 38 38
				38 38 38 38 38 38 38 38 38 38 38 38 38 38 38 38 38 38
				38 38 38 38 38 38 38 38 38 38 38 38 38 38 38 38 38 38
				38 38 38 38 38 38 38 38 38 38 38 38 38 38 38 38 38 38
				38 38 38 38 38 38 38 38 38 38 38 38 38 38 38 38 38 38
				38 38 38 38 38 38 38 38 38 38 38 38 38 38 38 38 38 38
				38 38 38 38 38 38 38 38 38 38 38 38 38 38 38 38 38 38
				38 38 38 38 38 38 38 38 38 38 38 38 38 38 38 38 38 38
				38 38 38 38 38 38 38 38 38 38 38 38 38 38 38 38 38 38
				38 38 38 38 38 38 38 38 38 38 38 38 38 38 38 38 38 38
				38 38 38 38 38 38 38 38 38 38 38 38 38 38 38 38 38 38
				38 38 38 38 38 38 38 38 38 38 38 38 38 38 38 38 38 38
				38 38 38 38 38 38 38 38 38 38 38 38 38 38 38 38 38 38
				38 38 38 38 38 38 38 38 38 38 38 38 38 38 38 38 38 38
				38 38 38 38 38 38 38 38 38 38 38 38 38 38 38 38 38 38
				38 38 38 38 38 38 38 38 38 38 38 38 38 38 38 38 38 38
				38 38 38 38 38 38 38 38 38 38 38 38 38 38 38 38 38 38
				38 38 38 38 38 38 38 38 38 38 38 38 38 38 38 38 38 38
				38 38 38 38 38 38 38 38 38 38 38 38 38 38 38 38 38 38
				38 38 38 38 38 38 38 38 38 38 38 38 38 38 38 38 38 38
				38 38 38 38 38 38 38 38 38 38 38 38 38 38 38 38 38 38
				38 38 38 38 38 38 38 38 38 38 38 38 38 38 38 38 38 38
				38 38 38 38 38 38 38 38 38 38 38 38 38 38 38 38 38 38
				38 38 38 38 38 38 38 38 38 38 38 38 38 38 38 38 38 38
				38 38 38 38 38 38 38 38 38 38 38 38 38 38 38 38 38 38
				38 38 38 38 38 38 38 38 38 38 38 38 38 38 38 38 38 38
				38 38 38 38 38 38 38 38 38 38 38 38 38 38 38 38 38 38
				38 38 38 38 38 38 38 38 38 38 38 38 38 38 38 38 38 38
				38 38 38 38 38 38 38 38 38 38 38 38 38 38 38 38 38 38
				38 38 38 38 38 38 38 38 38 38 38 38 38 38 38 38 38 38
				38 38 38>;

			PS_Config_Lmt_FW_CC_N = <
				9 9 9 9 9 9 9 9 9 9 9 9 9 9 9 9 9 9
				9 9 9 9 9 9 9 9 9 9 9 9 9 9 9 9 9 9
				9 9 9 9 9 9 9 9 9 9 9 9 9 9 9 9 9 9
				9 9 9 9 9 9 9 9 9 9 9 9 9 9 9 9 9 9
				9 9 9 9 9 9 9 9 9 9 9 9 9 9 9 9 9 9
				9 9 9 9 9 9 9 9 9 9 9 9 9 9 9 9 9 9
				9 9 9 9 9 9 9 9 9 9 9 9 9 9 9 9 9 9
				9 9 9 9 9 9 9 9 9 9 9 9 9 9 9 9 9 9
				9 9 9 9 9 9 9 9 9 9 9 9 9 9 9 9 9 9
				9 9 9 9 9 9 9 9 9 9 9 9 9 9 9 9 9 9
				9 9 9 9 9 9 9 9 9 9 9 9 9 9 9 9 9 9
				9 9 9 9 9 9 9 9 9 9 9 9 9 9 9 9 9 9
				9 9 9 9 9 9 9 9 9 9 9 9 9 9 9 9 9 9
				9 9 9 9 9 9 9 9 9 9 9 9 9 9 9 9 9 9
				9 9 9 9 9 9 9 9 9 9 9 9 9 9 9 9 9 9
				9 9 9 9 9 9 9 9 9 9 9 9 9 9 9 9 9 9
				9 9 9 9 9 9 9 9 9 9 9 9 9 9 9 9 9 9
				9 9 9 9 9 9 9 9 9 9 9 9 9 9 9 9 9 9
				9 9 9 9 9 9 9 9 9 9 9 9 9 9 9 9 9 9
				9 9 9 9 9 9 9 9 9 9 9 9 9 9 9 9 9 9
				9 9 9 9 9 9 9 9 9 9 9 9 9 9 9 9 9 9
				9 9 9 9 9 9 9 9 9 9 9 9 9 9 9 9 9 9
				9 9 9 9 9 9 9 9 9 9 9 9 9 9 9 9 9 9
				9 9 9 9 9 9 9 9 9 9 9 9 9 9 9 9 9 9
				9 9 9 9 9 9 9 9 9 9 9 9 9 9 9 9 9 9
				9 9 9 9 9 9 9 9 9 9 9 9 9 9 9 9 9 9
				9 9 9 9 9 9 9 9 9 9 9 9 9 9 9 9 9 9
				9 9 9 9 9 9 9 9 9 9 9 9 9 9 9 9 9 9
				9 9 9 9 9 9 9 9 9 9 9 9 9 9 9 9 9 9
				9 9 9 9 9 9 9 9 9 9 9 9 9 9 9 9 9 9
				9 9 9 9 9 9 9 9 9 9 9 9 9 9 9 9 9 9
				9 9 9 9 9 9 9 9 9 9 9 9 9 9 9 9 9 9
				9 9 9>;

			PS_Config_Lmt_FW_CC_I_P = <
				25 25 25 25 25 25 25 25 25 25 25 25 25 25 25 25 25 25
				25 25 25 25 25 25 25 25 25 25 25 25 25 25 25 25 25 25
				25 25 25 25 25 25 25 25 25 25 25 25 25 25 25 25 25 25
				25 25 25 25 25 25 25 25 25 25 25 25 25 25 25 25 25 25
				25 25 25 25 25 25 25 25 25 25 25 25 25 25 25 25 25 25
				25 25 25 25 25 25 25 25 25 25 25 25 25 25 25 25 25 25
				25 25 25 25 25 25 25 25 25 25 25 25 25 25 25 25 25 25
				25 25 25 25 25 25 25 25 25 25 25 25 25 25 25 25 25 25
				25 25 25 25 25 25 25 25 25 25 25 25 25 25 25 25 25 25
				25 25 25 25 25 25 25 25 25 25 25 25 25 25 25 25 25 25
				25 25 25 25 25 25 25 25 25 25 25 25 25 25 25 25 25 25
				25 25 25 25 25 25 25 25 25 25 25 25 25 25 25 25 25 25
				25 25 25 25 25 25 25 25 25 25 25 25 25 25 25 25 25 25
				25 25 25 25 25 25 25 25 25 25 25 25 25 25 25 25 25 25
				25 25 25 25 25 25 25 25 25 25 25 25 25 25 25 25 25 25
				25 25 25 25 25 25 25 25 25 25 25 25 25 25 25 25 25 25
				25 25 25 25 25 25 25 25 25 25 25 25 25 25 25 25 25 25
				25 25 25 25 25 25 25 25 25 25 25 25 25 25 25 25 25 25
				25 25 25 25 25 25 25 25 25 25 25 25 25 25 25 25 25 25
				25 25 25 25 25 25 25 25 25 25 25 25 25 25 25 25 25 25
				25 25 25 25 25 25 25 25 25 25 25 25 25 25 25 25 25 25
				25 25 25 25 25 25 25 25 25 25 25 25 25 25 25 25 25 25
				25 25 25 25 25 25 25 25 25 25 25 25 25 25 25 25 25 25
				25 25 25 25 25 25 25 25 25 25 25 25 25 25 25 25 25 25
				25 25 25 25 25 25 25 25 25 25 25 25 25 25 25 25 25 25
				25 25 25 25 25 25 25 25 25 25 25 25 25 25 25 25 25 25
				25 25 25 25 25 25 25 25 25 25 25 25 25 25 25 25 25 25
				25 25 25 25 25 25 25 25 25 25 25 25 25 25 25 25 25 25
				25 25 25 25 25 25 25 25 25 25 25 25 25 25 25 25 25 25
				25 25 25 25 25 25 25 25 25 25 25 25 25 25 25 25 25 25
				25 25 25 25 25 25 25 25 25 25 25 25 25 25 25 25 25 25
				25 25 25 25 25 25 25 25 25 25 25 25 25 25 25 25 25 25
				25 25 25>;

			PS_Config_Lmt_FW_CC_I_N = <
				0 0 0 0 0 0 0 0 0 0 0 0 0 0 0 0 0 0
				0 0 0 0 0 0 0 0 0 0 0 0 0 0 0 0 0 0
				0 0 0 0 0 0 0 0 0 0 0 0 0 0 0 0 0 0
				0 0 0 0 0 0 0 0 0 0 0 0 0 0 0 0 0 0
				0 0 0 0 0 0 0 0 0 0 0 0 0 0 0 0 0 0
				0 0 0 0 0 0 0 0 0 0 0 0 0 0 0 0 0 0
				0 0 0 0 0 0 0 0 0 0 0 0 0 0 0 0 0 0
				0 0 0 0 0 0 0 0 0 0 0 0 0 0 0 0 0 0
				0 0 0 0 0 0 0 0 0 0 0 0 0 0 0 0 0 0
				0 0 0 0 0 0 0 0 0 0 0 0 0 0 0 0 0 0
				0 0 0 0 0 0 0 0 0 0 0 0 0 0 0 0 0 0
				0 0 0 0 0 0 0 0 0 0 0 0 0 0 0 0 0 0
				0 0 0 0 0 0 0 0 0 0 0 0 0 0 0 0 0 0
				0 0 0 0 0 0 0 0 0 0 0 0 0 0 0 0 0 0
				0 0 0 0 0 0 0 0 0 0 0 0 0 0 0 0 0 0
				0 0 0 0 0 0 0 0 0 0 0 0 0 0 0 0 0 0
				0 0 0 0 0 0 0 0 0 0 0 0 0 0 0 0 0 0
				0 0 0 0 0 0 0 0 0 0 0 0 0 0 0 0 0 0
				0 0 0 0 0 0 0 0 0 0 0 0 0 0 0 0 0 0
				0 0 0 0 0 0 0 0 0 0 0 0 0 0 0 0 0 0
				0 0 0 0 0 0 0 0 0 0 0 0 0 0 0 0 0 0
				0 0 0 0 0 0 0 0 0 0 0 0 0 0 0 0 0 0
				0 0 0 0 0 0 0 0 0 0 0 0 0 0 0 0 0 0
				0 0 0 0 0 0 0 0 0 0 0 0 0 0 0 0 0 0
				0 0 0 0 0 0 0 0 0 0 0 0 0 0 0 0 0 0
				0 0 0 0 0 0 0 0 0 0 0 0 0 0 0 0 0 0
				0 0 0 0 0 0 0 0 0 0 0 0 0 0 0 0 0 0
				0 0 0 0 0 0 0 0 0 0 0 0 0 0 0 0 0 0
				0 0 0 0 0 0 0 0 0 0 0 0 0 0 0 0 0 0
				0 0 0 0 0 0 0 0 0 0 0 0 0 0 0 0 0 0
				0 0 0 0 0 0 0 0 0 0 0 0 0 0 0 0 0 0
				0 0 0 0 0 0 0 0 0 0 0 0 0 0 0 0 0 0
				0 0 0>;

			PS_Config_Lmt_FW_CC_Q_P = <
				25 25 25 25 25 25 25 25 25 25 25 25 25 25 25 25 25 25
				25 25 25 25 25 25 25 25 25 25 25 25 25 25 25 25 25 25
				25 25 25 25 25 25 25 25 25 25 25 25 25 25 25 25 25 25
				25 25 25 25 25 25 25 25 25 25 25 25 25 25 25 25 25 25
				25 25 25 25 25 25 25 25 25 25 25 25 25 25 25 25 25 25
				25 25 25 25 25 25 25 25 25 25 25 25 25 25 25 25 25 25
				25 25 25 25 25 25 25 25 25 25 25 25 25 25 25 25 25 25
				25 25 25 25 25 25 25 25 25 25 25 25 25 25 25 25 25 25
				25 25 25 25 25 25 25 25 25 25 25 25 25 25 25 25 25 25
				25 25 25 25 25 25 25 25 25 25 25 25 25 25 25 25 25 25
				25 25 25 25 25 25 25 25 25 25 25 25 25 25 25 25 25 25
				25 25 25 25 25 25 25 25 25 25 25 25 25 25 25 25 25 25
				25 25 25 25 25 25 25 25 25 25 25 25 25 25 25 25 25 25
				25 25 25 25 25 25 25 25 25 25 25 25 25 25 25 25 25 25
				25 25 25 25 25 25 25 25 25 25 25 25 25 25 25 25 25 25
				25 25 25 25 25 25 25 25 25 25 25 25 25 25 25 25 25 25
				25 25 25 25 25 25 25 25 25 25 25 25 25 25 25 25 25 25
				25 25 25 25 25 25 25 25 25 25 25 25 25 25 25 25 25 25
				25 25 25 25 25 25 25 25 25 25 25 25 25 25 25 25 25 25
				25 25 25 25 25 25 25 25 25 25 25 25 25 25 25 25 25 25
				25 25 25 25 25 25 25 25 25 25 25 25 25 25 25 25 25 25
				25 25 25 25 25 25 25 25 25 25 25 25 25 25 25 25 25 25
				25 25 25 25 25 25 25 25 25 25 25 25 25 25 25 25 25 25
				25 25 25 25 25 25 25 25 25 25 25 25 25 25 25 25 25 25
				25 25 25 25 25 25 25 25 25 25 25 25 25 25 25 25 25 25
				25 25 25 25 25 25 25 25 25 25 25 25 25 25 25 25 25 25
				25 25 25 25 25 25 25 25 25 25 25 25 25 25 25 25 25 25
				25 25 25 25 25 25 25 25 25 25 25 25 25 25 25 25 25 25
				25 25 25 25 25 25 25 25 25 25 25 25 25 25 25 25 25 25
				25 25 25 25 25 25 25 25 25 25 25 25 25 25 25 25 25 25
				25 25 25 25 25 25 25 25 25 25 25 25 25 25 25 25 25 25
				25 25 25 25 25 25 25 25 25 25 25 25 25 25 25 25 25 25
				25 25 25>;

			PS_Config_Lmt_FW_CC_Q_N = <
				0 0 0 0 0 0 0 0 0 0 0 0 0 0 0 0 0 0
				0 0 0 0 0 0 0 0 0 0 0 0 0 0 0 0 0 0
				0 0 0 0 0 0 0 0 0 0 0 0 0 0 0 0 0 0
				0 0 0 0 0 0 0 0 0 0 0 0 0 0 0 0 0 0
				0 0 0 0 0 0 0 0 0 0 0 0 0 0 0 0 0 0
				0 0 0 0 0 0 0 0 0 0 0 0 0 0 0 0 0 0
				0 0 0 0 0 0 0 0 0 0 0 0 0 0 0 0 0 0
				0 0 0 0 0 0 0 0 0 0 0 0 0 0 0 0 0 0
				0 0 0 0 0 0 0 0 0 0 0 0 0 0 0 0 0 0
				0 0 0 0 0 0 0 0 0 0 0 0 0 0 0 0 0 0
				0 0 0 0 0 0 0 0 0 0 0 0 0 0 0 0 0 0
				0 0 0 0 0 0 0 0 0 0 0 0 0 0 0 0 0 0
				0 0 0 0 0 0 0 0 0 0 0 0 0 0 0 0 0 0
				0 0 0 0 0 0 0 0 0 0 0 0 0 0 0 0 0 0
				0 0 0 0 0 0 0 0 0 0 0 0 0 0 0 0 0 0
				0 0 0 0 0 0 0 0 0 0 0 0 0 0 0 0 0 0
				0 0 0 0 0 0 0 0 0 0 0 0 0 0 0 0 0 0
				0 0 0 0 0 0 0 0 0 0 0 0 0 0 0 0 0 0
				0 0 0 0 0 0 0 0 0 0 0 0 0 0 0 0 0 0
				0 0 0 0 0 0 0 0 0 0 0 0 0 0 0 0 0 0
				0 0 0 0 0 0 0 0 0 0 0 0 0 0 0 0 0 0
				0 0 0 0 0 0 0 0 0 0 0 0 0 0 0 0 0 0
				0 0 0 0 0 0 0 0 0 0 0 0 0 0 0 0 0 0
				0 0 0 0 0 0 0 0 0 0 0 0 0 0 0 0 0 0
				0 0 0 0 0 0 0 0 0 0 0 0 0 0 0 0 0 0
				0 0 0 0 0 0 0 0 0 0 0 0 0 0 0 0 0 0
				0 0 0 0 0 0 0 0 0 0 0 0 0 0 0 0 0 0
				0 0 0 0 0 0 0 0 0 0 0 0 0 0 0 0 0 0
				0 0 0 0 0 0 0 0 0 0 0 0 0 0 0 0 0 0
				0 0 0 0 0 0 0 0 0 0 0 0 0 0 0 0 0 0
				0 0 0 0 0 0 0 0 0 0 0 0 0 0 0 0 0 0
				0 0 0 0 0 0 0 0 0 0 0 0 0 0 0 0 0 0
				0 0 0>;

			PS_Config_Lmt_FW_Diff_P = <
				35 35 35 35 35 35 35 35 35 35 35 35 35 35 35 35 35 35
				35 35 35 35 35 35 35 35 35 35 35 35 35 35 35 35 35 35
				35 35 35 35 35 35 35 35 35 35 35 35 35 35 35 35 35 35
				35 35 35 35 35 35 35 35 35 35 35 35 35 35 35 35 35 35
				35 35 35 35 35 35 35 35 35 35 35 35 35 35 35 35 35 35
				35 35 35 35 35 35 35 35 35 35 35 35 35 35 35 35 35 35
				35 35 35 35 35 35 35 35 35 35 35 35 35 35 35 35 35 35
				35 35 35 35 35 35 35 35 35 35 35 35 35 35 35 35 35 35
				35 35 35 35 35 35 35 35 35 35 35 35 35 35 35 35 35 35
				35 35 35 35 35 35 35 35 35 35 35 35 35 35 35 35 35 35
				35 35 35 35 35 35 35 35 35 35 35 35 35 35 35 35 35 35
				35 35 35 35 35 35 35 35 35 35 35 35 35 35 35 35 35 35
				35 35 35 35 35 35 35 35 35 35 35 35 35 35 35 35 35 35
				35 35 35 35 35 35 35 35 35 35 35 35 35 35 35 35 35 35
				35 35 35 35 35 35 35 35 35 35 35 35 35 35 35 35 35 35
				35 35 35 35 35 35 35 35 35 35 35 35 35 35 35 35 35 35
				35 35 35 35 35 35 35 35 35 35 35 35 35 35 35 35 35 35
				35 35 35 35 35 35 35 35 35 35 35 35 35 35 35 35 35 35
				35 35 35 35 35 35 35 35 35 35 35 35 35 35 35 35 35 35
				35 35 35 35 35 35 35 35 35 35 35 35 35 35 35 35 35 35
				35 35 35 35 35 35 35 35 35 35 35 35 35 35 35 35 35 35
				35 35 35 35 35 35 35 35 35 35 35 35 35 35 35 35 35 35
				35 35 35 35 35 35 35 35 35 35 35 35 35 35 35 35 35 35
				35 35 35 35 35 35 35 35 35 35 35 35 35 35 35 35 35 35
				35 35 35 35 35 35 35 35 35 35 35 35 35 35 35 35 35 35
				35 35 35 35 35 35 35 35 35 35 35 35 35 35 35 35 35 35
				35 35 35 35 35 35 35 35 35 35 35 35 35 35 35 35 35 35
				35 35 35 35 35 35 35 35 35 35 35 35 35 35 35 35 35 35
				35 35 35 35 35 35 35 35 35 35 35 35 35 35 35 35 35 35
				35 35 35 35 35 35 35 35 35 35 35 35 35 35 35 35 35 35
				35 35 35 35 35 35 35 35 35 35 35 35 35 35 35 35 35 35
				35 35 35 35 35 35 35 35 35 35 35 35 35 35 35 35 35 35
				35 35 35>;

			PS_Config_Lmt_FW_Diff_N = <
				(-35) (-35) (-35) (-35) (-35) (-35) (-35) (-35) (-35) (-35) (-35) (-35) (-35) (-35) (-35) (-35) (-35) (-35)
				(-35) (-35) (-35) (-35) (-35) (-35) (-35) (-35) (-35) (-35) (-35) (-35) (-35) (-35) (-35) (-35) (-35) (-35)
				(-35) (-35) (-35) (-35) (-35) (-35) (-35) (-35) (-35) (-35) (-35) (-35) (-35) (-35) (-35) (-35) (-35) (-35)
				(-35) (-35) (-35) (-35) (-35) (-35) (-35) (-35) (-35) (-35) (-35) (-35) (-35) (-35) (-35) (-35) (-35) (-35)
				(-35) (-35) (-35) (-35) (-35) (-35) (-35) (-35) (-35) (-35) (-35) (-35) (-35) (-35) (-35) (-35) (-35) (-35)
				(-35) (-35) (-35) (-35) (-35) (-35) (-35) (-35) (-35) (-35) (-35) (-35) (-35) (-35) (-35) (-35) (-35) (-35)
				(-35) (-35) (-35) (-35) (-35) (-35) (-35) (-35) (-35) (-35) (-35) (-35) (-35) (-35) (-35) (-35) (-35) (-35)
				(-35) (-35) (-35) (-35) (-35) (-35) (-35) (-35) (-35) (-35) (-35) (-35) (-35) (-35) (-35) (-35) (-35) (-35)
				(-35) (-35) (-35) (-35) (-35) (-35) (-35) (-35) (-35) (-35) (-35) (-35) (-35) (-35) (-35) (-35) (-35) (-35)
				(-35) (-35) (-35) (-35) (-35) (-35) (-35) (-35) (-35) (-35) (-35) (-35) (-35) (-35) (-35) (-35) (-35) (-35)
				(-35) (-35) (-35) (-35) (-35) (-35) (-35) (-35) (-35) (-35) (-35) (-35) (-35) (-35) (-35) (-35) (-35) (-35)
				(-35) (-35) (-35) (-35) (-35) (-35) (-35) (-35) (-35) (-35) (-35) (-35) (-35) (-35) (-35) (-35) (-35) (-35)
				(-35) (-35) (-35) (-35) (-35) (-35) (-35) (-35) (-35) (-35) (-35) (-35) (-35) (-35) (-35) (-35) (-35) (-35)
				(-35) (-35) (-35) (-35) (-35) (-35) (-35) (-35) (-35) (-35) (-35) (-35) (-35) (-35) (-35) (-35) (-35) (-35)
				(-35) (-35) (-35) (-35) (-35) (-35) (-35) (-35) (-35) (-35) (-35) (-35) (-35) (-35) (-35) (-35) (-35) (-35)
				(-35) (-35) (-35) (-35) (-35) (-35) (-35) (-35) (-35) (-35) (-35) (-35) (-35) (-35) (-35) (-35) (-35) (-35)
				(-35) (-35) (-35) (-35) (-35) (-35) (-35) (-35) (-35) (-35) (-35) (-35) (-35) (-35) (-35) (-35) (-35) (-35)
				(-35) (-35) (-35) (-35) (-35) (-35) (-35) (-35) (-35) (-35) (-35) (-35) (-35) (-35) (-35) (-35) (-35) (-35)
				(-35) (-35) (-35) (-35) (-35) (-35) (-35) (-35) (-35) (-35) (-35) (-35) (-35) (-35) (-35) (-35) (-35) (-35)
				(-35) (-35) (-35) (-35) (-35) (-35) (-35) (-35) (-35) (-35) (-35) (-35) (-35) (-35) (-35) (-35) (-35) (-35)
				(-35) (-35) (-35) (-35) (-35) (-35) (-35) (-35) (-35) (-35) (-35) (-35) (-35) (-35) (-35) (-35) (-35) (-35)
				(-35) (-35) (-35) (-35) (-35) (-35) (-35) (-35) (-35) (-35) (-35) (-35) (-35) (-35) (-35) (-35) (-35) (-35)
				(-35) (-35) (-35) (-35) (-35) (-35) (-35) (-35) (-35) (-35) (-35) (-35) (-35) (-35) (-35) (-35) (-35) (-35)
				(-35) (-35) (-35) (-35) (-35) (-35) (-35) (-35) (-35) (-35) (-35) (-35) (-35) (-35) (-35) (-35) (-35) (-35)
				(-35) (-35) (-35) (-35) (-35) (-35) (-35) (-35) (-35) (-35) (-35) (-35) (-35) (-35) (-35) (-35) (-35) (-35)
				(-35) (-35) (-35) (-35) (-35) (-35) (-35) (-35) (-35) (-35) (-35) (-35) (-35) (-35) (-35) (-35) (-35) (-35)
				(-35) (-35) (-35) (-35) (-35) (-35) (-35) (-35) (-35) (-35) (-35) (-35) (-35) (-35) (-35) (-35) (-35) (-35)
				(-35) (-35) (-35) (-35) (-35) (-35) (-35) (-35) (-35) (-35) (-35) (-35) (-35) (-35) (-35) (-35) (-35) (-35)
				(-35) (-35) (-35) (-35) (-35) (-35) (-35) (-35) (-35) (-35) (-35) (-35) (-35) (-35) (-35) (-35) (-35) (-35)
				(-35) (-35) (-35) (-35) (-35) (-35) (-35) (-35) (-35) (-35) (-35) (-35) (-35) (-35) (-35) (-35) (-35) (-35)
				(-35) (-35) (-35) (-35) (-35) (-35) (-35) (-35) (-35) (-35) (-35) (-35) (-35) (-35) (-35) (-35) (-35) (-35)
				(-35) (-35) (-35) (-35) (-35) (-35) (-35) (-35) (-35) (-35) (-35) (-35) (-35) (-35) (-35) (-35) (-35) (-35)
				(-35) (-35) (-35)>;

			PS_Config_Diff_Test_Frame = <50>;
		};
	};

};
